# STM32H7P4xx register map
File version: 1.0
Registers are 32-bit, read-write, reset 0x0 unless marked. A register's access mark holds for its fields unless they carry their own. Offsets are from the block's base; [hi:lo] are bit positions; {n}, {i} and the like mark numbered series.

## CRC — CRC calculation unit (CRC)
Base 0x58024C00
0x00 DR — CRC Data register
  [31:0] DR — Data register bits
0x04 IDR — CRC Independent data register
  [31:0] IDR — General-purpose 32-bits data register bits
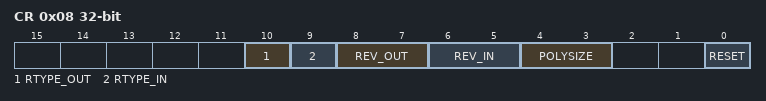
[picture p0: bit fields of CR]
0x08 CR — CRC Control register
  [10] RTYPE_OUT — Reverse type output
  [9] RTYPE_IN — Reverse type input
  [8:7] REV_OUT — REV_OUT Reverse Output Data bits
  [6:5] REV_IN — REV_IN Reverse Input Data bits
  [4:3] POLYSIZE — Polynomial size bits
  [0] RESET — RESET the CRC computation unit bit
0x10 INIT — Initial CRC value register
  [31:0] CRC_INIT — Programmable initial CRC value
0x14 POL — CRC polynomial register
  [31:0] POL — Coefficients of the polynomial

## RAMECC2 — RAM ECC monitoring (RAMECC)
Base 0x58027000
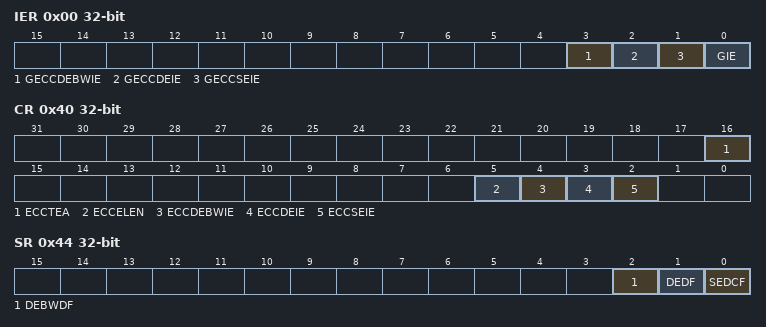
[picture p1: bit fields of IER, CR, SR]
0x00 IER — RAMECC interrupt enable register
  [3] GECCDEBWIE
  [2] GECCDEIE
  [1] GECCSEIE
  [0] GIE — Global interrupt enable
0x40 CR — RAMECC monitor configuration register
  [16] ECCTEA — ECC test ECC access
  [5] ECCELEN — ECC error latching enable
  [4] ECCDEBWIE
  [3] ECCDEIE — ECC double error interrupt enable
  [2] ECCSEIE — ECC single error interrupt enable
0x44 SR — RAMECC monitor status register
  [2] DEBWDF
  [1] DEDF — ECC double error detected flag
  [0] SEDCF
0x48 FAR ro — RAMECC monitor failing address register
  [31:0] FADD — ECC error failing address
0x4C FDR ro — RAMECC monitor failing data register
  [31:0] FDATA — Failing data
0x54 FECR ro — RAMECC monitor failing ECC error code register
  [31:0] FEC — Failing error code

## DBGMCU
Base 0x5C001000
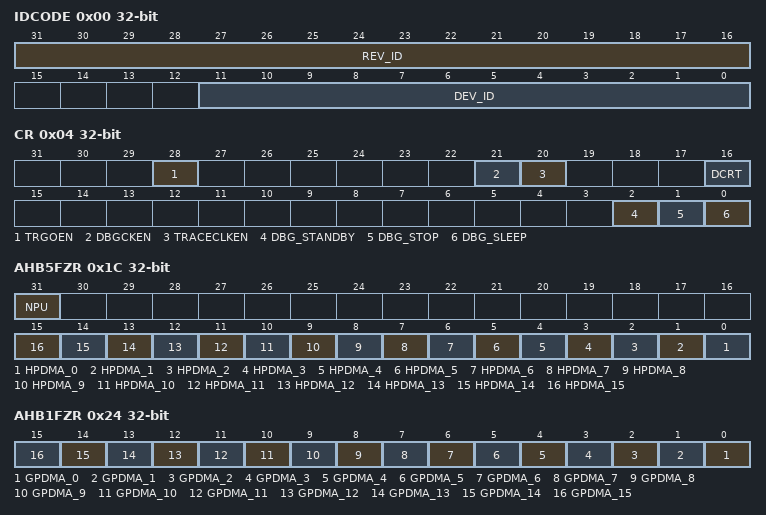
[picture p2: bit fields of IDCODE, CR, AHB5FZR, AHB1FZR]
0x00 IDCODE ro — DBGMCU identity code register
  [31:16] REV_ID — ID revision
  [11:0] DEV_ID — Device ID
0x04 CR — DBGMCU configuration register
  [28] TRGOEN — External trigger output enable
  [21] DBGCKEN — Debug clock enable
  [20] TRACECLKEN — Trace port clock enable
  [16] DCRT — Debug credentials reset type
  [2] DBG_STANDBY — Debug in Standby mode enable
  [1] DBG_STOP — Debug in Stop mode enable
  [0] DBG_SLEEP — Debug in Sleep mode enable
0x1C AHB5FZR — DBGMCU AHB5 peripheral freeze register
  [31] NPU — NPU stop in debug
  [n] HPDMA_{n} (n=0..15) — HPDMA channel {n} stop in debug
0x24 AHB1FZR — DBGMCU AHB1 peripheral freeze register
  [n] GPDMA_{n} (n=0..15) — GPDMA channel {n} stop in debug
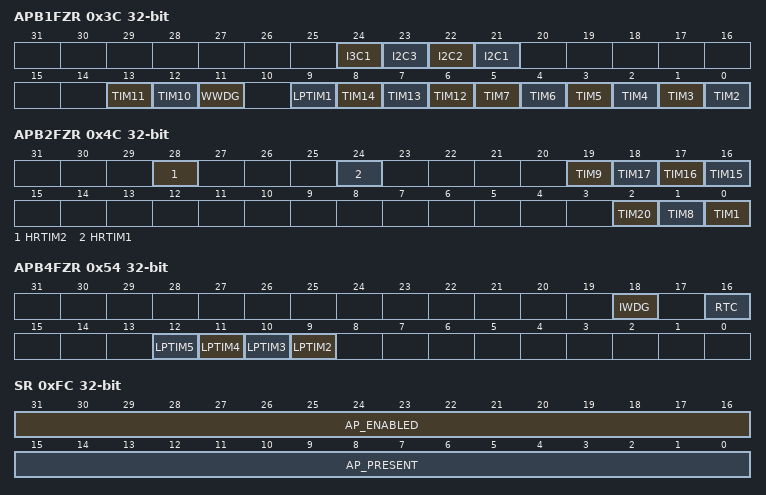
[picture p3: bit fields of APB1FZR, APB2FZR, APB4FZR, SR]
0x3C APB1FZR — DBGMCU APB1 peripheral freeze register
  [24] I3C1 — I3C1 SMBUS timeout stop in debug
  [23] I2C3 — I2C3 SMBUS timeout stop in debug
  [22] I2C2 — I2C2 SMBUS timeout stop in debug
  [21] I2C1 — I2C1 SMBUS timeout stop in debug
  [13] TIM11 — TIM11 stop in debug
  [12] TIM10 — TIM10 stop in debug
  [11] WWDG — WWDG stop in debug
  [9] LPTIM1 — LPTIM1 stop in debug
  [8] TIM14 — TIM14 stop in debug
  [7] TIM13 — TIM13 stop in debug
  [6] TIM12 — TIM12 stop in debug
  [n-2] TIM{n} (n=2..7) — TIM{n} stop in debug
0x4C APB2FZR — DBGMCU APB2 peripheral freeze register
  [28] HRTIM2 — HRTIM2 stop in debug
  [24] HRTIM1 — HRTIM1 stop in debug
  [19] TIM9 — TIM9 stop in debug
  [18] TIM17 — TIM17 stop in debug
  [17] TIM16 — TIM16 stop in debug
  [16] TIM15 — TIM15 stop in debug
  [2] TIM20 — TIM20/PWM20 stop in debug
  [1] TIM8 — TIM8/PWM8 stop in debug
  [0] TIM1 — TIM1/PWM1 stop in debug
0x54 APB4FZR — DBGMCU APB4 peripheral freeze register
  [18] IWDG — Independent watchdog for stop in debug
  [16] RTC — RTC stop in debug
  [n+7] LPTIM{n} (n=2..5) — LPTIM{n} stop in debug
0x80 EDBGRQ — DBGMCU EDBGRQ input control
  [0] DBG_CPU — CPU external debug request (EDBGRQ) signal driver
0xFC SR ro — DBGMCU status register
  [31:16] AP_ENABLED — APn port enable
  [15:0] AP_PRESENT — APn presence
0x100 DBG_AUTH_HOST — DBGMCU debug authentication mailbox host register
  [31:0] MESSAGE — Debug host to device mailbox message
0x104 DBG_AUTH_DEVICE — DBGMCU debug authentication mailbox device register
  [31:0] MESSAGE — Device to debug host mailbox message
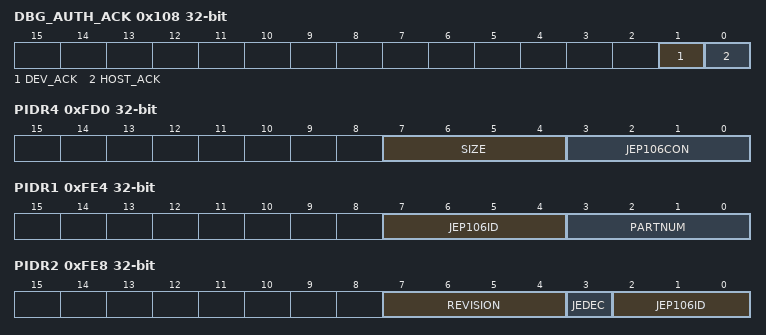
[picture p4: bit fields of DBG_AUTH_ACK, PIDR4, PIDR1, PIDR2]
0x108 DBG_AUTH_ACK — DBGMCU debug authentication mailbox acknowledge register
  [1] DEV_ACK — Device to device acknowledge
  [0] HOST_ACK — Host to device acknowledge
0xFD0 PIDR4 ro — DBGMCU peripheral identity register 4
  [7:4] SIZE — Register file size
  [3:0] JEP106CON — JEP106 continuation code
0xFE0 PIDR0 ro — DBGMCU peripheral identity register 0
  [7:0] PARTNUM — Part number field, bits [7:0]
0xFE4 PIDR1 ro — DBGMCU peripheral identity register 1
  [7:4] JEP106ID — JEP106 identity code field, bits [3:0]
  [3:0] PARTNUM — Part number field, bits [11:8]
0xFE8 PIDR2 ro — DBGMCU peripheral identity register 2
  [7:4] REVISION — Component revision number
  [3] JEDEC — JEDEC assigned value
  [2:0] JEP106ID — JEP106 identity code field, bits [6:4]
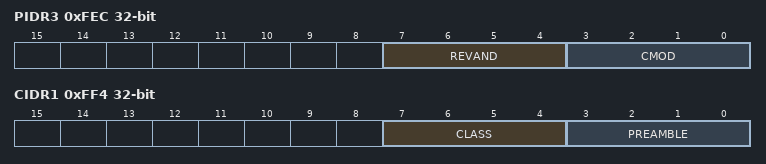
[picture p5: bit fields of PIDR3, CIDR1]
0xFEC PIDR3 ro — DBGMCU peripheral identity register 3
  [7:4] REVAND — Metal fix version
  [3:0] CMOD — Customer modified
0xFF0 CIDR0 ro — DBGMCU component identity register
  [7:0] PREAMBLE — Component ID field, bits [7:0]
0xFF4 CIDR1 ro — DBGMCU component identity register
  [7:4] CLASS — Component ID field, bits [15:12] - component class
  [3:0] PREAMBLE — Component ID field, bits [11:8]
0xFF8 CIDR2 ro — DBGMCU component identity register
  [7:0] PREAMBLE — Component ID field, bits [23:16]
0xFFC CIDR3 ro — DBGMCU component identity register
  [7:0] PREAMBLE — Component ID field, bits [31:24]

## AXIM
Base 0xBFF00000
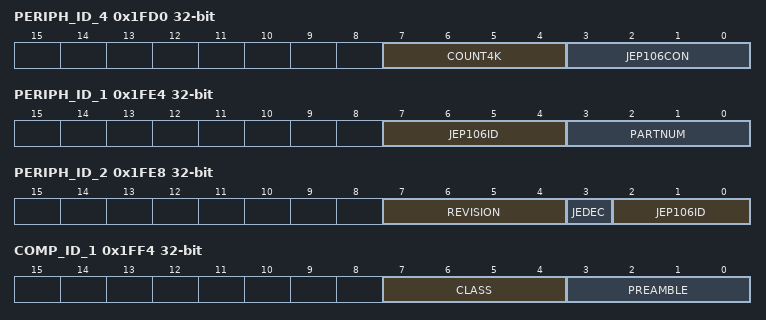
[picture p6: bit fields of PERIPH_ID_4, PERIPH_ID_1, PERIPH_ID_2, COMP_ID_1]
0x1FD0 PERIPH_ID_4 ro — AXI interconnect - peripheral ID4 register
  [7:4] COUNT4K, [3:0] JEP106CON
0x1FE0 PERIPH_ID_0 ro — AXI interconnect - peripheral ID0 register
  [7:0] PARTNUM
0x1FE4 PERIPH_ID_1 ro — AXI interconnect - peripheral ID1 register
  [7:4] JEP106ID, [3:0] PARTNUM
0x1FE8 PERIPH_ID_2 ro — AXI interconnect - peripheral ID2 register
  [7:4] REVISION, [3] JEDEC, [2:0] JEP106ID
0x1FF0 COMP_ID_0 ro — AXI interconnect - component ID0 register
  [7:0] PREAMBLE
0x1FF4 COMP_ID_1 ro — AXI interconnect - component ID1 register
  [7:4] CLASS, [3:0] PREAMBLE
0x1FF8 COMP_ID_2 ro — AXI interconnect - component ID2 register
  [7:0] PREAMBLE
0x1FFC COMP_ID_3 ro — AXI interconnect - component ID3 register
  [7:0] PREAMBLE
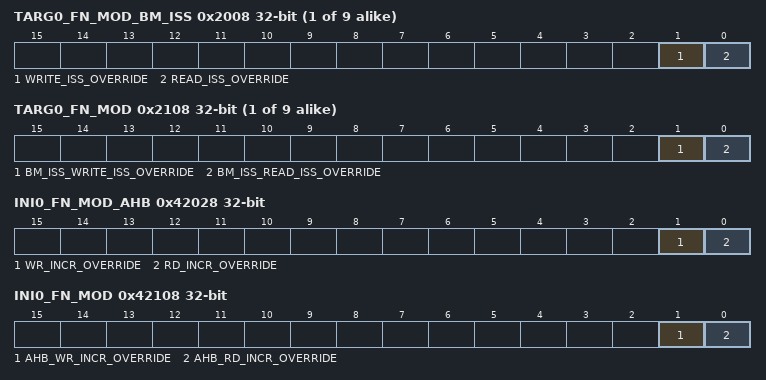
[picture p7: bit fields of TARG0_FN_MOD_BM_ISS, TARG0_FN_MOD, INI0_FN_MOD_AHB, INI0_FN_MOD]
{0x2008+0x1000*i} TARG{i}_FN_MOD_BM_ISS (i=0..8) — TARG bus matrix issuing functionality register
  [1] WRITE_ISS_OVERRIDE, [0] READ_ISS_OVERRIDE
0x2024 TARG0_FN_MOD2 — TARG bus matrix functionality register
  [0] BYPASS_MERGE
0x202C TARG0_FN_MOD_LB — TARG long burst functionality modification register
  [0] FN_MOD_LB
{0x2108+0x1000*i} TARG{i}_FN_MOD (i=0..8) — TARG issuing functionality modification register
  [1] BM_ISS_WRITE_ISS_OVERRIDE, [0] BM_ISS_READ_ISS_OVERRIDE
0xA024 TARG8_FN_MOD2 — TARG bus matrix functionality register
  [0] BYPASS_MERGE
0xA02C TARG8_FN_MOD_LB — TARG long burst functionality modification register
  [0] FN_MOD_LB
0x42024 INI0_FN_MOD2 — INI functionality modification register
  [0] BYPASS_MERGE
0x42028 INI0_FN_MOD_AHB — INI functionality modification AHB register
  [1] WR_INCR_OVERRIDE, [0] RD_INCR_OVERRIDE
{0x42100+0x1000*i} INI{i}_READ_QOS (i=0..5) — INI read QoS register
  [3:0] RQOS
{0x42104+0x1000*i} INI{i}_WRITE_QOS (i=0..5) — INI write QoS register
  [3:0] WQOS
0x42108 INI0_FN_MOD — INI issuing functionality modification register
  [1] AHB_WR_INCR_OVERRIDE, [0] AHB_RD_INCR_OVERRIDE
0x43024 INI1_FN_MOD2 — INI functionality modification register
  [0] BYPASS_MERGE
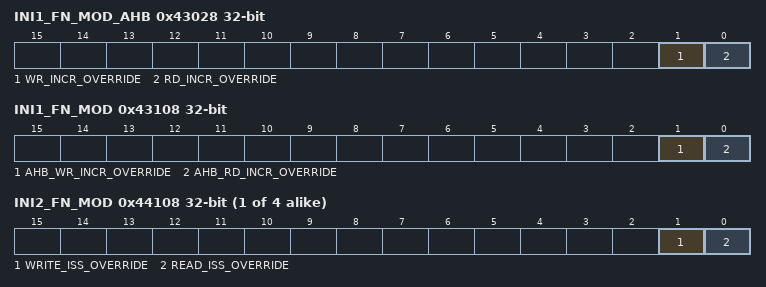
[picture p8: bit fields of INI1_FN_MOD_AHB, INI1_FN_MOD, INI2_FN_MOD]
0x43028 INI1_FN_MOD_AHB — INI functionality modification AHB register
  [1] WR_INCR_OVERRIDE, [0] RD_INCR_OVERRIDE
0x43108 INI1_FN_MOD — INI issuing functionality modification register
  [1] AHB_WR_INCR_OVERRIDE, [0] AHB_RD_INCR_OVERRIDE
{0x42108+0x1000*i} INI{i}_FN_MOD (i=2..5) — INI issuing functionality modification register
  [1] WRITE_ISS_OVERRIDE, [0] READ_ISS_OVERRIDE
